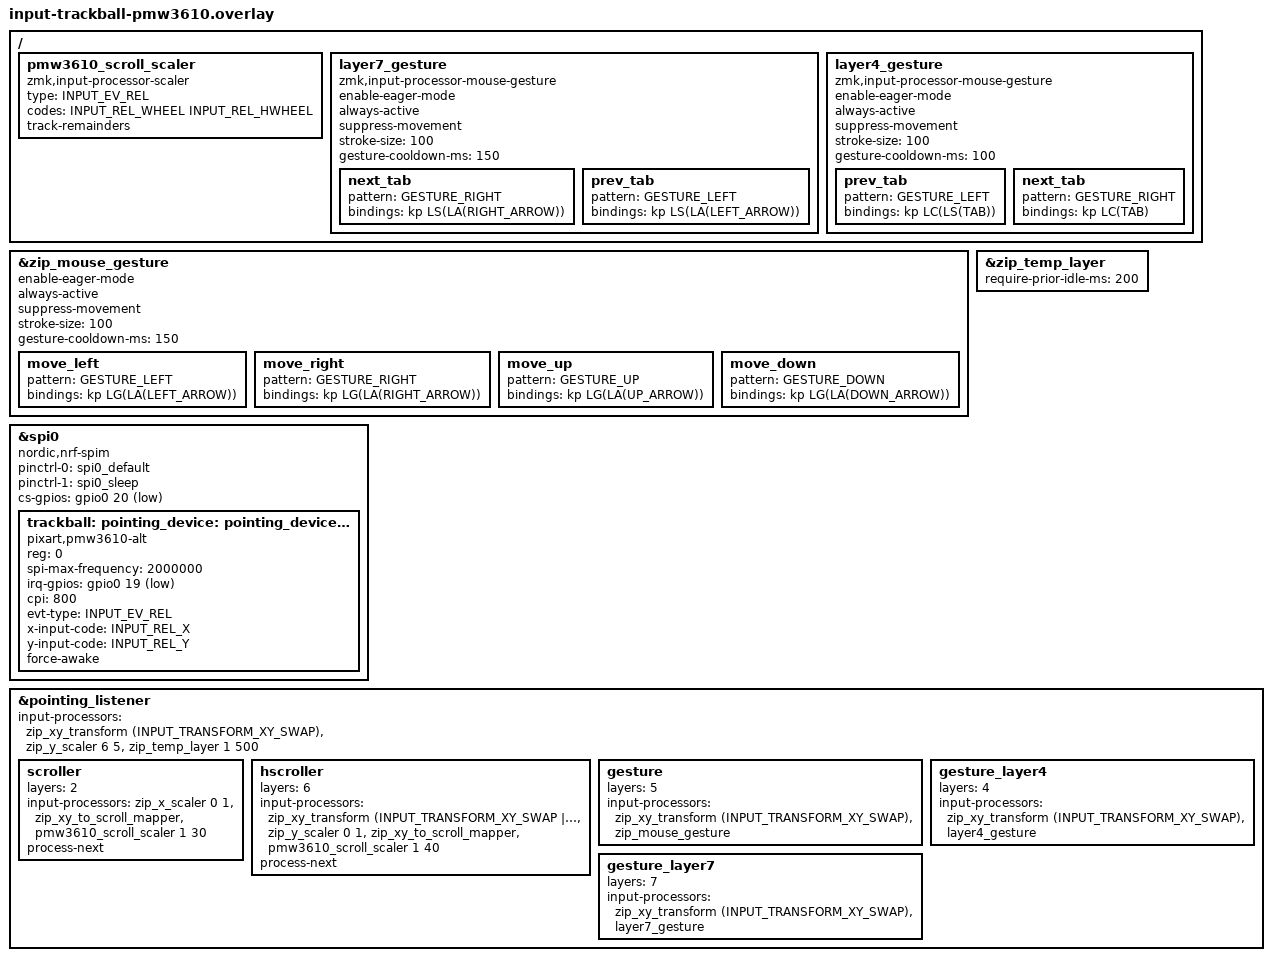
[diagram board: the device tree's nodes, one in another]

#include <dt-bindings/zmk/input_transform.h>
#include <dt-bindings/zmk/keys.h>
#include <mouse-gesture.dtsi>
#include <dt-bindings/zmk/mouse-gesture.h>

/ {
    pmw3610_scroll_scaler: pmw3610_scroll_scaler {
        compatible = "zmk,input-processor-scaler";
        #input-processor-cells = <2>;
        type = <INPUT_EV_REL>;
        codes = <INPUT_REL_WHEEL INPUT_REL_HWHEEL>;
        track-remainders;
    };

    // レイヤー7用のジェスチャー設定
    layer7_gesture: layer7_gesture {
        compatible = "zmk,input-processor-mouse-gesture";
        #input-processor-cells = <0>;
        enable-eager-mode;
        always-active;
        suppress-movement;
        stroke-size = <100>;
        gesture-cooldown-ms = <150>;

        next_tab {
            pattern = <GESTURE_RIGHT>;
            bindings = <&kp LS(LA(RIGHT_ARROW))>;  // Shift+Alt+→
        };
        prev_tab {
            pattern = <GESTURE_LEFT>;
            bindings = <&kp LS(LA(LEFT_ARROW))>;   // Shift+Alt+←
        };
    };

    // レイヤー4用のジェスチャー設定(Chromeタブ切り替え、左右2方向)。
    // レイヤー5と中身を入れ替えたため、旧レイヤー5の内容がここに入っている
    layer4_gesture: layer4_gesture {
        compatible = "zmk,input-processor-mouse-gesture";
        #input-processor-cells = <0>;
        enable-eager-mode;
        always-active;
        suppress-movement;
        stroke-size = <100>;
        gesture-cooldown-ms = <100>;

        prev_tab {
            pattern = <GESTURE_LEFT>;
            bindings = <&kp LC(LS(TAB))>;  // Ctrl+Shift+Tab (Chromeで左のタブへ)
        };
        next_tab {
            pattern = <GESTURE_RIGHT>;
            bindings = <&kp LC(TAB)>;      // Ctrl+Tab (Chromeで右のタブへ)
        };
    };
};

// レイヤー5用のジェスチャー設定(ウィンドウ移動、4方向)。
// レイヤー4と中身を入れ替えたため、旧レイヤー4の内容がここに入っている
&zip_mouse_gesture {
    enable-eager-mode;
    always-active;                // レイヤー5に入っている間、起動キーなしで自動的にジェスチャー認識をONにする
    suppress-movement;            // ジェスチャー中はカーソルを動かさない(素通しでマウスが動いてしまうのを防ぐ)
    stroke-size = <100>;           // 1回のジェスチャーと認識される移動量の閾値。小さくするほど、長くスーッと動かした時に短い距離で連続して切り替わるようになる
    gesture-cooldown-ms = <150>;   // 連続発火を許可する最短間隔(時間ベース)

    move_left {
        pattern = <GESTURE_LEFT>;
        bindings = <&kp LG(LA(LEFT_ARROW))>;   // Cmd+Option+←
    };
    move_right {
        pattern = <GESTURE_RIGHT>;
        bindings = <&kp LG(LA(RIGHT_ARROW))>;  // Cmd+Option+→
    };
    move_up {
        pattern = <GESTURE_UP>;
        bindings = <&kp LG(LA(UP_ARROW))>;     // Cmd+Option+↑
    };
    move_down {
        pattern = <GESTURE_DOWN>;
        bindings = <&kp LG(LA(DOWN_ARROW))>;   // Cmd+Option+↓
    };
};

&spi0 {
    status = "okay";
    compatible = "nordic,nrf-spim";
    pinctrl-0 = <&spi0_default>;
    pinctrl-1 = <&spi0_sleep>;
    pinctrl-names = "default", "sleep";
    cs-gpios = <&gpio0 20 GPIO_ACTIVE_LOW>;

    trackball: pointing_device: pointing_device@0 {
        status = "okay";
        compatible = "pixart,pmw3610-alt";
        reg = <0>;
        spi-max-frequency = <2000000>;
        irq-gpios = <&gpio0 19 (GPIO_ACTIVE_LOW | GPIO_PULL_UP)>;
        cpi = <800>;
        evt-type = <INPUT_EV_REL>;
        x-input-code = <INPUT_REL_X>;
        y-input-code = <INPUT_REL_Y>;
        force-awake;
    };
};

&zip_temp_layer {
    require-prior-idle-ms = <200>;
};

&pointing_listener {
    input-processors =
        <&zip_xy_transform (INPUT_TRANSFORM_XY_SWAP)>,
        <&zip_y_scaler 6 5>,
        <&zip_temp_layer 1 500>;

    scroller {
        layers = <2>;
        input-processors =
            // XY_SWAPを外すことで、センサーの生のY軸(=物理的な左右方向の動き)を
            // 縦スクロールの入力として使う。Y_INVERTを外して向きを反転する
            <&zip_x_scaler 0 1>,
            <&zip_xy_to_scroll_mapper>,
            <&pmw3610_scroll_scaler 1 30>;  // 感度を1/20倍から1/30倍にさらに落とす
        process-next;
    };

    hscroller {
        layers = <6>;
        input-processors =
            // XY_SWAPを追加することで、センサーの生のY軸(=物理的な左右方向の動き)を
            // 横スクロールの入力として使う。X_INVERTを追加して向きを反転する
            <&zip_xy_transform (INPUT_TRANSFORM_XY_SWAP | INPUT_TRANSFORM_X_INVERT)>,
            <&zip_y_scaler 0 1>,
            <&zip_xy_to_scroll_mapper>,
            <&pmw3610_scroll_scaler 1 40>;  // 縦スクロール(1/30倍)の3/4倍(=3/120=1/40倍)を維持したまま感度を落とす
        process-next;
    };

    gesture {
        layers = <5>;
        input-processors =
            // 通常のカーソル移動と同じXY_SWAP補正をかけてから渡すことで、
            // 物理的な左右の動きがジェスチャー判定の「左右」と一致するようにする
            <&zip_xy_transform (INPUT_TRANSFORM_XY_SWAP)>,
            <&zip_mouse_gesture>;
    };

    gesture_layer4 {
        layers = <4>;
        input-processors =
            <&zip_xy_transform (INPUT_TRANSFORM_XY_SWAP)>,
            <&layer4_gesture>;
    };

    gesture_layer7 {
        layers = <7>;
        input-processors =
            <&zip_xy_transform (INPUT_TRANSFORM_XY_SWAP)>,
            <&layer7_gesture>;
    };
};
